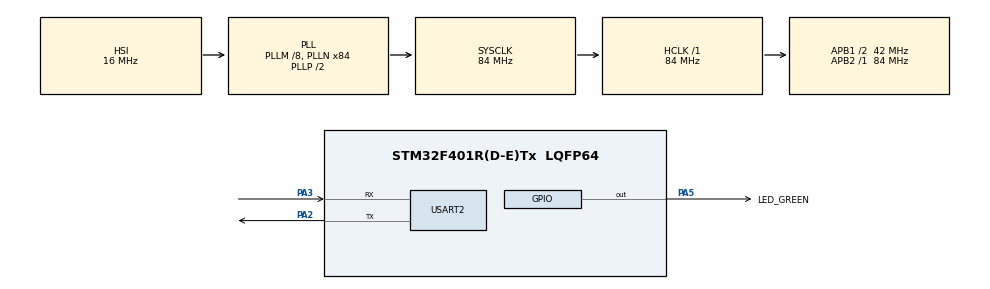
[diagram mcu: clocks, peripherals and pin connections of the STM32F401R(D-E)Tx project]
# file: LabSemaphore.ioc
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FREERTOS.BinarySemaphores01=myBinarySem01,Dynamic,NULL,Available
FREERTOS.Tasks01=myTask02,24,128,StartTask02,Default,NULL,Dynamic,NULL,NULL;myTask01,24,128,StartTask01,Default,NULL,Dynamic,NULL,NULL
Mcu.Family=STM32F4
Mcu.Name=STM32F401R(D-E)Tx
Mcu.Package=LQFP64
NVIC.PriorityGroup=NVIC_PRIORITYGROUP_4
NVIC.TIM1_TRG_COM_TIM11_IRQn=true\:15\:0\:false\:false\:true\:false\:false\:true\:true
NVIC.TimeBase=TIM1_TRG_COM_TIM11_IRQn
NVIC.TimeBaseIP=TIM11
PA2.Mode=Asynchronous
PA2.Signal=USART2_TX
PA3.Mode=Asynchronous
PA3.Signal=USART2_RX
PA5.GPIO_Label=LED_GREEN
PA5.Signal=GPIO_Output
ProjectManager.HeapSize=0x1000
ProjectManager.StackSize=0x1000
ProjectManager.TargetToolchain=CMake
RCC.48MHZClocksFreq_Value=42000000
RCC.AHBFreq_Value=84000000
RCC.APB1CLKDivider=RCC_HCLK_DIV2
RCC.APB1Freq_Value=42000000
RCC.APB1TimFreq_Value=84000000
RCC.APB2Freq_Value=84000000
RCC.APB2TimFreq_Value=84000000
RCC.CortexFreq_Value=84000000
RCC.HCLKFreq_Value=84000000
RCC.HSE_VALUE=25000000
RCC.HSI_VALUE=16000000
RCC.LSE_VALUE=32768
RCC.PLLM=8
RCC.PLLN=84
RCC.SYSCLKFreq_VALUE=84000000
RCC.SYSCLKSource=RCC_SYSCLKSOURCE_PLLCLK
RCC.VCOOutputFreq_Value=168000000
USART2.VirtualMode=VM_ASYNC
VP_FREERTOS_VS_CMSIS_V2.Mode=CMSIS_V2
VP_SYS_VS_tim11.Mode=TIM11
board=custom

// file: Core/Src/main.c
/* USER CODE BEGIN Header */
/**
  ******************************************************************************
  * @file           : main.c
  * @brief          : Main program body
  ******************************************************************************
  * @attention
  *
  * Copyright (c) 2026 STMicroelectronics.
  * All rights reserved.
  *
  * This software is licensed under terms that can be found in the LICENSE file
  * in the root directory of this software component.
  * If no LICENSE file comes with this software, it is provided AS-IS.
  *
  ******************************************************************************
  */
/* USER CODE END Header */
#include "main.h"
#include "cmsis_os.h"
#include "usart.h"
#include "gpio.h"

/* USER CODE BEGIN Includes */
#include "stdio.h"
/* USER CODE END Includes */

void SystemClock_Config(void);
void MX_FREERTOS_Init(void);

/* USER CODE BEGIN 0 */
int __io_putchar(uint8_t ch)
{
 HAL_UART_Transmit(&huart2, (uint8_t *)&ch,1 ,100);
 return ch;
}
/* USER CODE END 0 */

int main(void)
{

  /* MCU Configuration--------------------------------------------------------*/

  /* Reset of all peripherals, Initializes the Flash interface and the Systick. */
  HAL_Init();

  /* Configure the system clock */
  SystemClock_Config();

  /* Initialize all configured peripherals */
  MX_GPIO_Init();
  MX_USART2_UART_Init();

  /* Init scheduler */
  osKernelInitialize();  /* Call init function for freertos objects (in cmsis_os2.c) */
  MX_FREERTOS_Init();

  /* Start scheduler */
  osKernelStart();

  /* We should never get here as control is now taken by the scheduler */

  /* Infinite loop */
  while (1)
  {

  }
}

void SystemClock_Config(void)
{
  RCC_OscInitTypeDef RCC_OscInitStruct = {0};
  RCC_ClkInitTypeDef RCC_ClkInitStruct = {0};

  /** Configure the main internal regulator output voltage
  */
  __HAL_RCC_PWR_CLK_ENABLE();
  __HAL_PWR_VOLTAGESCALING_CONFIG(PWR_REGULATOR_VOLTAGE_SCALE2);

  /** Initializes the RCC Oscillators according to the specified parameters
  * in the RCC_OscInitTypeDef structure.
  */
  RCC_OscInitStruct.OscillatorType = RCC_OSCILLATORTYPE_HSI;
  RCC_OscInitStruct.HSIState = RCC_HSI_ON;
  RCC_OscInitStruct.HSICalibrationValue = RCC_HSICALIBRATION_DEFAULT;
  RCC_OscInitStruct.PLL.PLLState = RCC_PLL_ON;
  RCC_OscInitStruct.PLL.PLLSource = RCC_PLLSOURCE_HSI;
  RCC_OscInitStruct.PLL.PLLM = 8;
  RCC_OscInitStruct.PLL.PLLN = 84;
  RCC_OscInitStruct.PLL.PLLP = RCC_PLLP_DIV2;
  RCC_OscInitStruct.PLL.PLLQ = 4;
  if (HAL_RCC_OscConfig(&RCC_OscInitStruct) != HAL_OK)
  {
    Error_Handler();
  }

  /** Initializes the CPU, AHB and APB buses clocks
  */
  RCC_ClkInitStruct.ClockType = RCC_CLOCKTYPE_HCLK|RCC_CLOCKTYPE_SYSCLK
                              |RCC_CLOCKTYPE_PCLK1|RCC_CLOCKTYPE_PCLK2;
  RCC_ClkInitStruct.SYSCLKSource = RCC_SYSCLKSOURCE_PLLCLK;
  RCC_ClkInitStruct.AHBCLKDivider = RCC_SYSCLK_DIV1;
  RCC_ClkInitStruct.APB1CLKDivider = RCC_HCLK_DIV2;
  RCC_ClkInitStruct.APB2CLKDivider = RCC_HCLK_DIV1;

  if (HAL_RCC_ClockConfig(&RCC_ClkInitStruct, FLASH_LATENCY_2) != HAL_OK)
  {
    Error_Handler();
  }
}

void HAL_TIM_PeriodElapsedCallback(TIM_HandleTypeDef *htim)
{
  if (htim->Instance == TIM11)
  {
    HAL_IncTick();
  }
}

void Error_Handler(void)
{
  __disable_irq();
  while (1)
  {
  }
}

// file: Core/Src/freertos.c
/* USER CODE BEGIN Header */
/**
  ******************************************************************************
  * File Name          : freertos.c
  * Description        : Code for freertos applications
  ******************************************************************************
  * @attention
  *
  * Copyright (c) 2026 STMicroelectronics.
  * All rights reserved.
  *
  * This software is licensed under terms that can be found in the LICENSE file
  * in the root directory of this software component.
  * If no LICENSE file comes with this software, it is provided AS-IS.
  *
  ******************************************************************************
  */
/* USER CODE END Header */

#include "FreeRTOS.h"
#include "task.h"
#include "main.h"
#include "cmsis_os.h"

/* USER CODE BEGIN Includes */
#include "stdio.h"
/* USER CODE END Includes */

/* Definitions for myTask02 */
osThreadId_t myTask02Handle;
const osThreadAttr_t myTask02_attributes = {
  .name = "myTask02",
  .stack_size = 128 * 4,
  .priority = (osPriority_t) osPriorityNormal,
};
/* Definitions for myTask01 */
osThreadId_t myTask01Handle;
const osThreadAttr_t myTask01_attributes = {
  .name = "myTask01",
  .stack_size = 128 * 4,
  .priority = (osPriority_t) osPriorityNormal,
};
/* Definitions for myBinarySem01 */
osSemaphoreId_t myBinarySem01Handle;
const osSemaphoreAttr_t myBinarySem01_attributes = {
  .name = "myBinarySem01"
};

void StartTask02(void *argument);
void StartTask01(void *argument);

void MX_FREERTOS_Init(void); /* (MISRA C 2004 rule 8.1) */

void MX_FREERTOS_Init(void) {

  /* Create the semaphores(s) */
  /* creation of myBinarySem01 */
  myBinarySem01Handle = osSemaphoreNew(1, 1, &myBinarySem01_attributes);

  /* Create the thread(s) */
  /* creation of myTask02 */
  myTask02Handle = osThreadNew(StartTask02, NULL, &myTask02_attributes);

  /* creation of myTask01 */
  myTask01Handle = osThreadNew(StartTask01, NULL, &myTask01_attributes);

}

void StartTask02(void *argument)
{
  /* USER CODE BEGIN StartTask02 */
  /* Infinite loop */
  for(;;)
  {
    osSemaphoreAcquire(myBinarySem01Handle, 4000);
    printf("Task2 Synchronized\n");
    osDelay(500);
  }
  /* USER CODE END StartTask02 */
}

void StartTask01(void *argument)
{
  /* USER CODE BEGIN StartTask01 */
  /* Infinite loop */
  for(;;)
  {
    osDelay(2000);
    printf("Task1 Release Semaphore\n");
    osSemaphoreRelease(myBinarySem01Handle);
  }
  /* USER CODE END StartTask01 */
}
